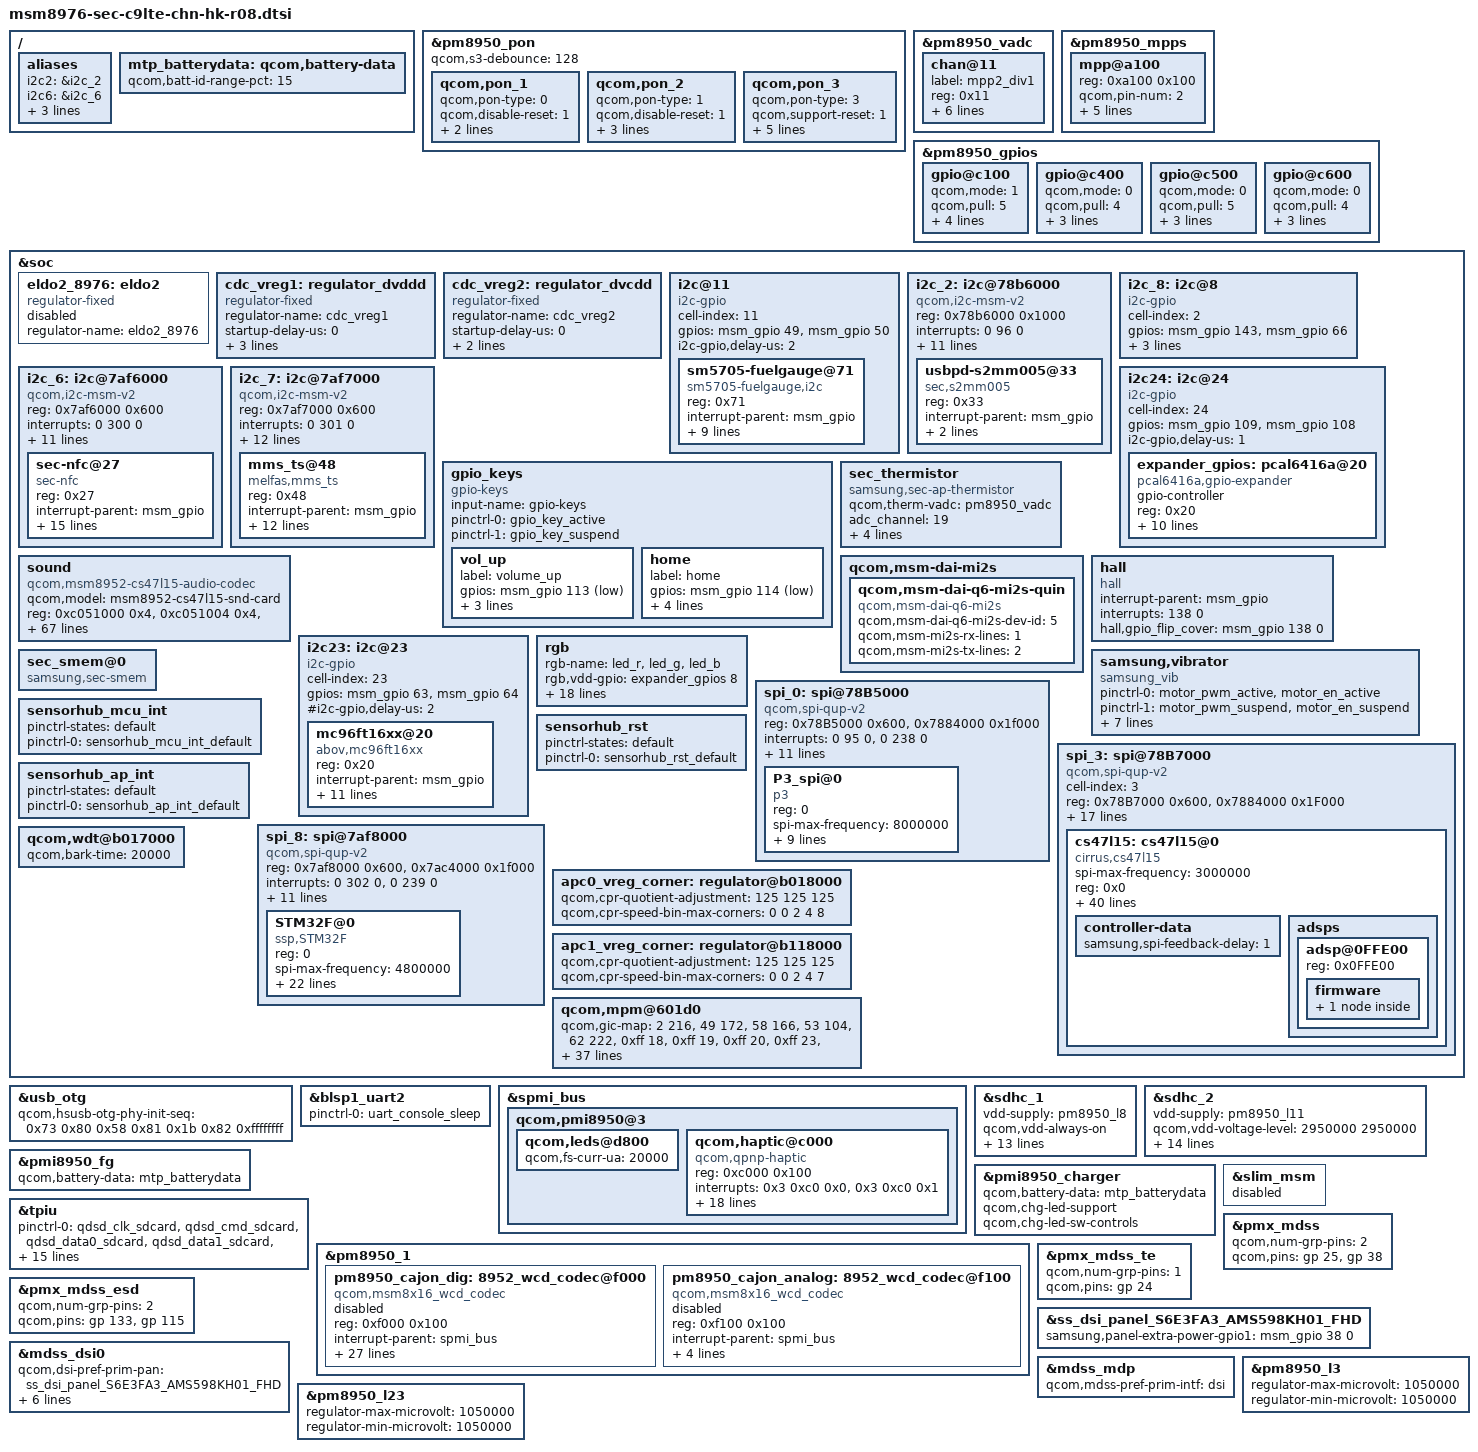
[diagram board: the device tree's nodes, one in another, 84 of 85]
/*
 * Copyright (c) 2015, The Linux Foundation. All rights reserved.
 *
 * This program is free software; you can redistribute it and/or modify
 * it under the terms of the GNU General Public License version 2 and
 * only version 2 as published by the Free Software Foundation.
 *
 * This program is distributed in the hope that it will be useful,
 * but WITHOUT ANY WARRANTY; without even the implied warranty of
 * MERCHANTABILITY or FITNESS FOR A PARTICULAR PURPOSE.  See the
 * GNU General Public License for more details.
 */

#include "../../qcom/msm8976-v1.1.dtsi"
#include "../../qcom/msm8976-pinctrl.dtsi"
#include "msm8976-sec-msm8976lte-common.dtsi"
//#include "msm8976-max77843.dtsi"
#include "msm8976-sec-pinctrl-c9lte-chn-hk-r08.dtsi"
#include "msm8976-sec-c9lte-chn-fingerprint-sensor_01.dtsi"
#include "msm8976-c9lte-sm5705-r02.dtsi"
#include "msm8976-sec-c9lte-chn-battery-r02.dtsi"
//#include "msm8976-sm5705.dtsi"
//#include "msm8976-s2mpb02.dtsi"
#include "msm8976-sec-a9xlte-chn-mst-r02.dtsi"
#include "msm8976-camera-sensor-c9lte-r01.dtsi"

/{
	aliases {
		i2c2 = &i2c_2;
		//i2c5 = &i2c_5;
		i2c6 = &i2c_6;
		i2c8 = &i2c_8;
		spi3 = &spi_3;
		spi8 = &spi_8;
	};
};

&pm8950_pon {
	qcom,s3-debounce = <128>;

	qcom,pon_1 {
		qcom,pon-type = <0>;
		qcom,disable-reset = <1>;
		qcom,pull-up = <1>;
		linux,code = <116>;
	};

	qcom,pon_2 {
		qcom,pon-type = <1>;
		qcom,disable-reset = <1>;
		qcom,support-reset = <0>;
		qcom,pull-up = <1>;
		linux,code = <114>;
	};

	qcom,pon_3 {
		qcom,pon-type = <3>;
		qcom,support-reset = <1>;
		qcom,pull-up = <1>;
		qcom,s1-timer = <6720>;
		qcom,s2-timer = <1000>;
		qcom,s2-type = <1>;
		qcom,use-bark;
	};
};

&pm8950_vadc {
	chan@11 {
		label = "mpp2_div1";
		reg = <0x11>;
		qcom,decimation = <0>;
		qcom,pre-div-channel-scaling = <0>; // 1:3scale
		qcom,calibration-type = "absolute";
		qcom,scale-function = <0>;
		qcom,hw-settle-time = <2>;
		qcom,fast-avg-setup = <0>;
	};
};

&pm8950_mpps {
	mpp@a100 {
		reg = <0xa100 0x100>;
		qcom,pin-num = <2>;
		status = "okay";
		qcom,mode = <4>; /* AIN input */
		qcom,invert = <1>; /* Enable MPP */
		qcom,ain-route = <1>; /* AMUX 6 */
		qcom,master-en = <1>;
		qcom,src-sel = <0>; /* Function constant */
	};
};

&pm8950_gpios {
	gpio@c100 {
		qcom,mode = <1>; // Digital output
		qcom,pull = <5>; // No Pull up
		qcom,vin-sel = <2>; // Vin select to 1 i.e.,  V
		qcom,src-sel = <2>; //special function 1
		qcom,master-en = <1>; //enable MPP
		qcom,out-strength = <2>; // Output strength medium
		status = "ok";
	};
	gpio@c400 {
                qcom,mode = <0>;
                qcom,pull = <4>;
                qcom,vin-sel = <2>;
                qcom,src-sel = <2>;
                qcom,master-en = <1>;
                status = "ok";
        };
	gpio@c500 {
		status = "ok";
		qcom,mode = <0>;
		qcom,pull = <5>;
		qcom,vin-sel = <3>;//VREG_L5, 1.8V
		qcom,src-sel = <0>;
		qcom,master-en = <1>;
	};
	gpio@c600 {
		status = "ok";
		qcom,mode = <0>;
		qcom,pull = <4>;
		qcom,vin-sel = <3>;//VREG_L5, 1.8V
		qcom,src-sel = <0>;
		qcom,master-en = <1>;
	};	
};

&soc {

	eldo2_8976: eldo2 {
		compatible = "regulator-fixed";
		regulator-name = "eldo2_8976";
		status = "disabled";
	};
		
	cdc_vreg1: regulator_dvddd {
        compatible = "regulator-fixed";
        regulator-name = "cdc_vreg1";
		status = "ok";
        startup-delay-us = <0>;
        enable-active-high;
        gpio = <&msm_gpio 74 0>;
		regulator-always-on;
    };

    cdc_vreg2: regulator_dvcdd {
        compatible = "regulator-fixed";
        regulator-name = "cdc_vreg2";
        startup-delay-us = <0>;
        enable-active-high;
		status = "ok";
        gpio = <&msm_gpio 75 0>;
    };

	i2c@11 {
		cell-index = <11>;
		compatible = "i2c-gpio";
		gpios = <&msm_gpio 49 0 /* sda */
			&msm_gpio 50 0	/* scl */
			>;
		i2c-gpio,delay-us = <2>;
		#address-cells = <1>;
		#size-cells = <0>;

		sm5705-fuelgauge@71{
			compatible = "sm5705-fuelgauge,i2c";
			reg = <0x71>;
			interrupt-parent = <&msm_gpio>;
			pinctrl-names = "default";
			pinctrl-0 = <&fg_i2c_active &fuel_int_active>;
			fuelgauge,irqf = "IRQF_TRIGGER_FALLING + IRQF_ONESHOT + IRQF_NO_SUSPEND";
			fuelgauge,fuel_int = <&msm_gpio 141 0x1>;
			fuelgauge,fuel_alert_soc = <1>;
			fuelgauge,capacity_max = <1000>;
			fuelgauge,capacity_max_margin = <70>;
			fuelgauge,capacity_min = <0>;
			fuelgauge,capacity_calculation_type = <0x1F>;
		};
	};


	i2c_2: i2c@78b6000 { /* BLSP1 QUP2 */
		compatible = "qcom,i2c-msm-v2";
		#address-cells = <1>;
		#size-cells = <0>;
		reg-names = "qup_phys_addr";
		reg = <0x78b6000 0x1000>;
		interrupt-names = "qup_irq";
		interrupts = <0 96 0>;
		qcom,clk-freq-out = <100000>;
		qcom,clk-freq-in  = <19200000>;
		clock-names = "iface_clk", "core_clk";
		clocks = <&clock_gcc clk_gcc_blsp1_ahb_clk>,
			<&clock_gcc clk_gcc_blsp1_qup2_i2c_apps_clk>;
		pinctrl-names = "i2c_active", "i2c_sleep";
		pinctrl-0 = <&i2c_2_active &s2mm005_irq_default>; 
		pinctrl-1 = <&i2c_2_sleep>;
		qcom,noise-rjct-scl = <0>;
		qcom,noise-rjct-sda = <0>;
		qcom,master-id = <86>;
		dmas = <&dma_blsp1 6 64 0x20000020 0x20>,
               		<&dma_blsp1 7 32 0x20000020 0x20>;
		dma-names = "tx", "rx";


		usbpd-s2mm005@33 {
			compatible = "sec,s2mm005";
			reg = <0x33>;
			interrupt-parent = <&msm_gpio>;
			interrupts = <107 0x0>;
			usbpd,usbpd_int = <&msm_gpio 107 0>;
		};
	};
	
	i2c_8:i2c@8 { /* SW I2C */
		cell-index = <2>;
		compatible = "i2c-gpio";
		gpios = <&msm_gpio 143 0 /* sda */
			&msm_gpio 66 0 /* scl */
		>;
		#i2c-gpio,delay-us = <2>;
		#address-cells = <1>;
		#size-cells = <0>;
		pinctrl-names = "default";
		pinctrl-0 = <&i2c_1_active>;
		pinctrl-1 = <&i2c_1_sleep>;
	
	};

#if 0
	i2c_5: i2c@7af5000 { /* BLSP2 QUP1 */
		compatible = "qcom,i2c-msm-v2";
		#address-cells = <1>;
		#size-cells = <0>;
		reg-names = "qup_phys_addr";
		reg = <0x7af5000 0x1000>;
		interrupt-names = "qup_irq";
		interrupts = <0 299 0>;
		qcom,clk-freq-out = <400000>;
		qcom,clk-freq-in  = <19200000>;
		clock-names = "iface_clk", "core_clk";
		clocks = <&clock_gcc clk_gcc_blsp2_ahb_clk>,
			 <&clock_gcc clk_gcc_blsp2_qup1_i2c_apps_clk>;

		pinctrl-names = "i2c_active", "i2c_sleep";
		pinctrl-0 = <&i2c_5_active>;
		pinctrl-1 = <&i2c_5_suspend>;
		qcom,noise-rjct-scl = <0>;
		qcom,noise-rjct-sda = <0>;
		qcom,master-id = <84>;
		dmas = <&dma_blsp2 4 64 0x20000020 0x20>,
			<&dma_blsp2 5 32 0x20000020 0x20>;
		dma-names = "tx", "rx";

		bhy@28 {
			compatible = "bhy";
			reg = <0x28>;
			interrupt-parent = <&msm_gpio>;
			interrupts = <142 0>;
			bhy,gpio_irq = <&msm_gpio 142 0x00>;
			bhy,ldo_enable = <&msm_gpio 69 0x01>;
			bhy,i2c-pull-up = <1>;
		};
	};
#endif
	i2c_6: i2c@7af6000 { /* BLSP2 QUP2 */
		compatible = "qcom,i2c-msm-v2";
		#address-cells = <1>;
		#size-cells = <0>;
		reg-names = "qup_phys_addr";
		reg = <0x7af6000 0x600>;
		interrupt-names = "qup_irq";
		interrupts = <0 300 0>;
		qcom,clk-freq-out = <400000>;
		qcom,clk-freq-in  = <19200000>;
		clock-names = "iface_clk", "core_clk";
		clocks = <&clock_gcc clk_gcc_blsp2_ahb_clk>,
			<&clock_gcc clk_gcc_blsp2_qup2_i2c_apps_clk>;
		pinctrl-names = "i2c_active", "i2c_sleep";
		pinctrl-0 = <&i2c_6_active>;
		pinctrl-1 = <&i2c_6_sleep>;
		qcom,noise-rjct-scl = <0>;
		qcom,noise-rjct-sda = <0>;
		qcom,master-id = <84>;
		dmas = <&dma_blsp2 6 64 0x20000020 0x20>,
			<&dma_blsp2 7 32 0x20000020 0x20>;
		dma-names = "tx", "rx";

		sec-nfc@27 {
			compatible = "sec-nfc";
			reg = <0x27>;
			interrupt-parent = <&msm_gpio>;
			interrupts = <21 0>;
			pinctrl-names = "nfc_active","nfc_suspend";
			pinctrl-0 = <&nfc_int_active &nfc_firmware_active &nfc_enable_active &nfc_pvdd_active>;
			pinctrl-1 = <&nfc_int_suspend &nfc_firmware_suspend &nfc_enable_suspend &nfc_pvdd_suspend>;
			sec-nfc,firm-gpio = <&msm_gpio 36 0x00>;
			sec-nfc,ven-gpio = <&msm_gpio 20 0x00>;
			sec-nfc,irq-gpio = <&msm_gpio 21 0x00>;
			sec-nfc,pvdd-gpio = <&msm_gpio 35 0x00>;
			qcom,clk-src = "BBCLK2";
			qcom,clk-gpio = <&pm8950_gpios 5 0x00>;
			clocks = <&clock_gcc clk_bb_clk2_pin>;
			clock-names = "rf_clk";
			sec-nfc,nfc_pm_clk;
		};
	};

	i2c_7: i2c@7af7000 { /* BLSP2 QUP3 */
		compatible = "qcom,i2c-msm-v2";
		#address-cells = <1>;
		#size-cells = <0>;
		reg-names = "qup_phys_addr";
		reg = <0x7af7000 0x600>;
		interrupt-names = "qup_irq";
		interrupts = <0 301 0>;
		qcom,master-id = <84>;
		qcom,clk-freq-out = <400000>;
		qcom,clk-freq-in  = <19200000>;
		clock-names = "iface_clk", "core_clk";
		clocks = <&clock_gcc clk_gcc_blsp2_ahb_clk>,
			<&clock_gcc clk_gcc_blsp2_qup3_i2c_apps_clk>;
		pinctrl-names = "i2c_active", "i2c_sleep";
		pinctrl-0 = <&i2c_7_active>;
		pinctrl-1 = <&i2c_7_suspend>;
		qcom,noise-rjct-scl = <0>;
		qcom,noise-rjct-sda = <0>;
		qcom,disable-dma;
		dmas = <&dma_blsp2 8 64 0x20000020 0x20>,
			<&dma_blsp2 9 32 0x20000020 0x20>;
		dma-names = "tx", "rx";
	};

	i2c24: i2c@24 { /* SW I2C */
		cell-index = <24>;
		compatible = "i2c-gpio";
		gpios = <&msm_gpio 109 0 /* sda */
			&msm_gpio 108 0 /* scl */
		>;
		i2c-gpio,delay-us = <1>;
		#address-cells = <1>;
		#size-cells = <0>;

		expander_gpios: pcal6416a@20 {
			compatible = "pcal6416a,gpio-expander";
			gpio-controller;
			#gpio-cells = <2>;
			reg = <0x20>;
			pinctrl-names = "expander_reset_setting";
			pinctrl-0 = <&expander_reset_active &expander_i2c_active>;
			pcal6416a,gpio_start = <300>;
			pcal6416a,ngpio = <16>;
			pcal6416a,reset-gpio = <&msm_gpio 51 0x00>;
			pcal6416a,vdd-supply = <&pm8950_l5>;
			pcal6416a,support_initialize = <1>;
			/* config, 15 ~ 0, 1bit configure[1:input, 0:output]*/
			pcal6416a,config = <0x5EE0>;    /* 0101 1110 1110 0000 */
			/* data_out, 15 ~ 0, 1bit configure[1:high, 0:low]*/
			pcal6416a,data_out = <0x0000>;  /* 0000 0000 0000 0000  */
			/* pull_reg, 31 ~ 0, 2bit configure[00:no_pull, 01:pull_down, 10:pull_up, 11:not used]*/
			pcal6416a,pull_reg = <0x04000145>; /* 00 00 01 00 / 00 00 00 00 /  00 00 00 01 / 01 00 01 01 */
		};
	};

	gpio_keys {
		compatible = "gpio-keys";
		input-name = "gpio-keys";
		pinctrl-names = "tlmm_gpio_key_active","tlmm_gpio_key_suspend";
		pinctrl-0 = <&gpio_key_active>;
		pinctrl-1 = <&gpio_key_suspend>;

		vol_up {
			label = "volume_up";
			gpios = <&msm_gpio 113 0x1>;
			linux,input-type = <1>;
			linux,code = <115>;
			debounce-interval = <15>;
		};

		home {
			label = "home";
			gpios = <&msm_gpio 114 0x1>;
			linux,input-type = <1>;
			linux,code = <172>;
			gpio-key,wakeup;
			debounce-interval = <15>;
		};
	};

	sec_thermistor {
		compatible = "samsung,sec-ap-thermistor";
		qcom,therm-vadc = <&pm8950_vadc>;
		status = "okay";
		adc_channel = <19>;
		adc_array = <25724 26467 26647 27010 27342 27620 27790 27976 28195 28425 28679 28962 29162 29405 29799 30559 31394 32464 33361 34338 35634 36245 37056 37585 37919 38083 38861 39764 40457 41041 41518>;

		temp_array = <900 800 750 700 650 620 600 580 570 550 530 510 490 470 450 400 350 300 250 200 150 100 80 50 30 10 0 (-50) (-100) (-150) (-200)>;
	};

	/delete-node/ wcd_gpio_ctrl;
	/delete-node/ sound-9335;

	sound {
		compatible = "qcom,msm8952-cs47l15-audio-codec";
		qcom,model = "msm8952-cs47l15-snd-card";
		reg = <0xc051000 0x4>,
		      <0xc051004 0x4>,
		      <0xc055000 0x4>,
		      <0xc052000 0x4>;
		reg-names = "csr_gp_io_mux_mic_ctl",
			    "csr_gp_io_mux_spkr_ctl",
			    "csr_gp_io_lpaif_pri_pcm_pri_mode_muxsel",
			    "csr_gp_io_mux_quin_ctl";

		qcom,mpp-channel-scaling = <2 1 1>;
		qcom,earjack-read-vadc = <&pm8950_vadc>;
		qcom,msm-ext-pa = "quaternary";
		qcom,msm-mclk-freq = <9600000>;
		qcom,msm-mbhc-hphl-swh = <0>;
		qcom,msm-mbhc-gnd-swh = <0>;
		qcom,msm-hs-micbias-type = "internal";
		qcom,audio-routing =
			"RX_BIAS", "MCLK",
			"SPK_RX_BIAS", "MCLK",
			"INT_LDO_H", "MCLK",
			"MainMic","MICBIAS1B",
			"IN1AL","MainMic",
			"SubMic","MICBIAS1C",
			"IN1AR","SubMic",
			"HeadsetMic","MICBIAS1A",
			"IN1BL","HeadsetMic";
		qcom,msm-gpios =
			"quat_i2s",
			"quin_i2s";
		qcom,pinctrl-names =
			"all_off",
			"quat_i2s_act",
			"quin_i2s_act",
			"quin_quat_i2s_act";
		pinctrl-names =
			"all_off",
			"quat_i2s_act",
			"quin_i2s_act",
			"quin_quat_i2s_act";
		pinctrl-0 = <&quat_tlmm_lines_sus &quat_tlmm_lines2_sus &quin_tlmm_lines_sus &gp_clk1_suspend>;
		pinctrl-1 = <&quat_tlmm_lines_act &quat_tlmm_lines2_act &quin_tlmm_lines_sus &gp_clk1_suspend>;
		pinctrl-2 = <&quat_tlmm_lines_sus &quat_tlmm_lines2_sus &quin_tlmm_lines_act &gp_clk1_active>;
		pinctrl-3 = <&quat_tlmm_lines_act &quat_tlmm_lines2_act &quin_tlmm_lines_act &gp_clk1_active>;
		asoc-platform = <&pcm0>, <&pcm1>, <&pcm2>, <&voip>, <&voice>,
				<&loopback>, <&compress>, <&hostless>,
				<&afe>, <&lsm>, <&routing>, <&lpa>,
				<&voice_svc>;
		asoc-platform-names = "msm-pcm-dsp.0", "msm-pcm-dsp.1", "msm-pcm-dsp.2",
				"msm-voip-dsp", "msm-pcm-voice", "msm-pcm-loopback",
				"msm-compress-dsp", "msm-pcm-hostless", "msm-pcm-afe",
				"msm-lsm-client", "msm-pcm-routing", "msm-pcm-lpa",
				"msm-voice-svc";
		asoc-cpu = <&dai_pri_auxpcm>, <&dai_hdmi>,
				<&dai_mi2s0>, <&dai_mi2s1>, <&dai_mi2s2>, <&dai_mi2s3>,
				<&dai_mi2s5>, <&dai_mi2s6>,
				<&sb_0_rx>, <&sb_0_tx>, <&sb_1_rx>, <&sb_1_tx>,
				<&sb_3_rx>, <&sb_3_tx>, <&sb_4_rx>, <&sb_4_tx>,
				<&bt_sco_rx>, <&bt_sco_tx>, <&int_fm_rx>, <&int_fm_tx>,
				<&afe_pcm_rx>, <&afe_pcm_tx>, <&afe_proxy_rx>, <&afe_proxy_tx>,
				<&incall_record_rx>, <&incall_record_tx>, <&incall_music_rx>,
				<&incall_music_2_rx>;
		asoc-cpu-names = "msm-dai-q6-auxpcm.1", "msm-dai-q6-hdmi.8",
				"msm-dai-q6-mi2s.0", "msm-dai-q6-mi2s.1",
				"msm-dai-q6-mi2s.2", "msm-dai-q6-mi2s.3",
				"msm-dai-q6-mi2s.5", "msm-dai-q6-mi2s.6",
				"msm-dai-q6-dev.16384", "msm-dai-q6-dev.16385",
				"msm-dai-q6-dev.16386", "msm-dai-q6-dev.16387",
				"msm-dai-q6-dev.16390", "msm-dai-q6-dev.16391",
				"msm-dai-q6-dev.16392", "msm-dai-q6-dev.16393",
				"msm-dai-q6-dev.12288", "msm-dai-q6-dev.12289",
				"msm-dai-q6-dev.12292", "msm-dai-q6-dev.12293",
				"msm-dai-q6-dev.224", "msm-dai-q6-dev.225",
				"msm-dai-q6-dev.241", "msm-dai-q6-dev.240",
				"msm-dai-q6-dev.32771", "msm-dai-q6-dev.32772",
				"msm-dai-q6-dev.32773", "msm-dai-q6-dev.32770";
		asoc-codec = <&stub_codec>, <&pm8950_cajon_dig>;
		asoc-codec-names = "msm-stub-codec.1", "cajon_codec";
		
		clock-names = "ext-mclk";
		clocks = <&clock_gcc clk_gcc_camss_gp1_clk>;
		
		imp_table = <
			0 13 8
			14 26 8
			27 42 8
			43 100 19
			101 200 19
			201 450 19
			451 1000 19
			1001 9999 19
		>;
	};

	qcom,msm-dai-mi2s {
		qcom,msm-dai-q6-mi2s-quin {
			compatible = "qcom,msm-dai-q6-mi2s";
			qcom,msm-dai-q6-mi2s-dev-id = <5>;
			qcom,msm-mi2s-rx-lines = <1>;
			qcom,msm-mi2s-tx-lines = <2>;
		};
	};

	hall {
		status = "okay";
		compatible = "hall";
		interrupt-parent = <&msm_gpio>;
		interrupts = <138 0>;
		hall,gpio_flip_cover = <&msm_gpio 138 0>;
	};
#if 0
	certify_hall {
                status = "okay";
                compatible = "certify_hall";
                interrupt-parent = <&msm_gpio>;
                interrupts = <144 0>;
                certify_hall,gpio_certify_cover = <&msm_gpio 144 0>;
        };
#endif
	i2c23: i2c@23 { /* SW I2C */
		cell-index = <23>;
		compatible = "i2c-gpio";
		gpios = <&msm_gpio 63 0 /* sda */
			&msm_gpio 64 0 /* scl */
		>;
		#i2c-gpio,delay-us = <2>;
		#address-cells = <1>;
		#size-cells = <0>;

		mc96ft16xx@20{
			compatible = "abov,mc96ft16xx";
			reg = <0x20>;
			interrupt-parent = <&msm_gpio>;
			interrupts = <62 0>;
			pinctrl-names = "touchkey_active", "touchkey_suspend";
			pinctrl-0 = <&touchkey_i2c_active &touchkey_int_active>;
			pinctrl-1 = <&touchkey_i2c_suspend &touchkey_int_suspend>;
			abov,sda-gpio = <&msm_gpio 63 0>;
			abov,scl-gpio = <&msm_gpio 64 0>;
			abov,irq-gpio = <&msm_gpio 62 0>;
			abov,tkey_en-gpio = <&pm8950_gpios 7 0x00>;
			abov,firmware_name = "abov/abov_ft1604_c9.fw";
			vdd_led-supply = <&pm8950_l10>;
			//abov,tkey_led_en-gpio = <&msm_gpio 91 0>;
			//vddo-supply = <&pm8950_l6>;
		};
	};

	samsung,vibrator {
               compatible = "samsung_vib";
               pinctrl-names = "tlmm_motor_active","tlmm_motor_suspend";
               pinctrl-0 = <&motor_pwm_active &motor_en_active>;
               pinctrl-1 = <&motor_pwm_suspend &motor_en_suspend>;
	       samsung,vib_en = <&msm_gpio 118 1>;
               samsung,vib_pwm = <&msm_gpio 31 0x1>;
               samsung,gp_clk = <0x01854000>;   // Address of GP1 clock
               samsung,chip_model = <2>;         // using ISA driver
	       samsung,m_default = <3>;
	       samsung,n_default = <138>;
	       samsung,motor_strength = <98>;
               status = "ok";
       };

	rgb {
		device_type = <0>;
		rgb-name = "led_r", "led_g", "led_b";
		rgb,vdd-gpio = <&expander_gpios 8 0x0>;

		normal_powermode_current = <255>;
		low_powermode_current = <51>;
		br_ratio_r = <27>;
		br_ratio_g = <9>;
		br_ratio_b = <80>;
		br_ratio_b_low = <32>;

		normal_powermode_current_bk = <255>;
		low_powermode_current_bk = <51>;
		br_ratio_r_bk = <25>;
		br_ratio_g_bk = <9>;
		br_ratio_b_bk = <80>;
		br_ratio_b_low_bk = <32>;

		normal_powermode_current_wt = <255>;
		low_powermode_current_wt = <51>;
		br_ratio_r_wt = <27>;
		br_ratio_g_wt = <9>;
		br_ratio_b_wt = <80>;
		br_ratio_b_low_wt = <32>;
	};
	/delete-node/ spi@0x78B5000;

	spi_0: spi@78B5000 { /* BLSP1 QUP0 */
		status = "ok";
		compatible = "qcom,spi-qup-v2";
                #address-cells = <1>;
                #size-cells = <0>;
		reg-names = "spi_physical", "spi_bam_physical";
                reg = <0x78B5000 0x600>, <0x7884000 0x1f000>;
		interrupt-names = "spi_irq", "spi_bam_irq";
		interrupts = <0 95 0>, <0 238 0>;
		spi-max-frequency = <19200000>;
                qcom,master-id = <86>;

                qcom,use-bam;
                qcom,use-pinctrl;
                qcom,ver-reg-exists;
                qcom,bam-consumer-pipe-index = <4>;
                qcom,bam-producer-pipe-index = <5>;
		pinctrl-names = "spi_default", "spi_sleep";
		pinctrl-0 = <&spi0_default &spi0_cs0_active>;
		pinctrl-1 = <&spi0_sleep &spi0_cs0_sleep>;

                clock-names = "iface_clk", "core_clk";
		clocks = <&clock_gcc clk_gcc_blsp1_ahb_clk>,
			 <&clock_gcc clk_gcc_blsp1_qup1_spi_apps_clk>;

		P3_spi@0 {
			compatible = "p3";
			reg = <0>;
			spi-max-frequency = <8000000>;
			p3-mosipin = <&msm_gpio 0 0x0>;
			p3-misopin = <&msm_gpio 1 0x0>;
			p3-cspin = <&msm_gpio 2 0x0>;
			p3-clkpin = <&msm_gpio 3 0x0>;
			p3-ese_pwr_req = <&msm_gpio 100 0x0>;
			p3-test = <0xBB>;
			p3-ap_vendor = "qualcomm";
			clock-names = "pclk", "sclk";
			clocks = <&clock_gcc clk_gcc_blsp1_ahb_clk>,
			       <&clock_gcc clk_gcc_blsp1_qup1_spi_apps_clk>;
		};
	};
		
	spi_3: spi@78B7000 {
		status = "ok";
		compatible = "qcom,spi-qup-v2";
		cell-index = <3>;
		reg-names = "spi_physical", "spi_bam_physical";
		reg = <0x78B7000 0x600>,
			<0x7884000 0x1F000>;
		interrupt-names = "spi_irq", "spi_bam_irq";
		interrupts = <0 97 0>, <0 238 0>;
		spi-max-frequency = <19200000>;
		#address-cells = <1>;
		#size-cells = <0>;

		qcom,gpio-mosi = <&msm_gpio 8 0>;
		qcom,gpio-miso = <&msm_gpio 9 0>;
		qcom,gpio-cs0  = <&msm_gpio 10 0>;
		qcom,gpio-clk  = <&msm_gpio 11 0>;

		qcom,infinite-mode = <0>;
		qcom,use-bam;
		qcom,use-pinctrl;
		qcom,bam-consumer-pipe-index = <8>;
		qcom,bam-producer-pipe-index = <9>;
		qcom,ver-reg-exists;
		qcom,master-id = <86>;

		pinctrl-names = "spi_default", "spi_sleep";
		pinctrl-0 = <&spi_3_active &spi_3_clk_active>;
		pinctrl-1 = <&spi_3_sleep &spi_3_clk_sleep>;

		clock-names = "iface_clk", "core_clk";
		clocks = <&clock_gcc clk_gcc_blsp1_ahb_clk>,
		<&clock_gcc clk_gcc_blsp1_qup3_spi_apps_clk>;
		
		cs47l15: cs47l15@0 {
			spi-max-frequency = <3000000>;

			compatible = "cirrus,cs47l15";
			reg = <0x0>;
			interrupt-parent = <&msm_gpio>;
            interrupts = <121 0>;
			interrupt-controller;
			#interrupt-cells = <2>;
			//interrupt-parent = <&gpx0>;
			gpio-controller;
			#gpio-cells = <2>;
			
			
			AVDD-supply = <&cdc_vreg1>;
            DCVDD-supply = <&cdc_vreg2>;
            DBVDD1-supply = <&cdc_vreg1>;
            CPVDD-supply = <&cdc_vreg1>;
            MICVDD-supply = <&cdc_vreg1>;
			SPKVDD-supply = <&pm8950_l5>;

			wlf,reset = <&msm_gpio 116 0>;
			//wlf,ldoena = <&expander_gpios 12 1>;//<&msm_gpio 75 0>;
			wlf,micd-bias-start-time = <1>;
			wlf,gpsw = <3>;
			wlf,micd-rate = <7>;
			wlf,micd-dbtime = <0x1>;
			wlf,micd-timeout = <1000>;
			wlf,micd-force-micbias;
			wlf,hpdet-short-circuit-imp = <3>;
			wlf,jd-wake-time = <5000>;
			wlf,micd-open-circuit-declare = <1>;
			
			// Moisture Detection
			wlf,hpdet-moisture-imp = <2000>;
			wlf,hpdet-moisture-debounce = <40>;
			
			wlf,micd-detect-debounce = <300>;
			wlf,micbias1 = <2800 0 1 1 1 1 0>;
			wlf,dmic-ref = <0 0 0>;
			wlf,inmode = <0 0 0>;
			wlf,hs-mic = <1>;
			wlf,hpdet-ext-res = <8>;
			wlf,micd-configs = <1 0 0 0>;
			wlf,micd-ranges = <
			 116 226
			 173 582
			 321 115
			 752 114
			 1257 217
			>;
			wlf,micd-clamp-mode = <0x8>;
			wlf,use-jd-gpio;
			wlf,micd-software-compare;
			wlf,init-mic-delay = <30>;
			
			wlf,dvbdd_ena = <&expander_gpios 10 1>;
			wlf,dcvdd_ena = <&expander_gpios 12 1>;//<&msm_gpio 75 0>;
			wlf,ear_switch_ena = <&expander_gpios 9 1>;

			wlf,gpio-defaults = <
				0x00002000 0x00006000 /* AIF1TXDAT (GPIO1) */
				0x00002000 0x00006000 /* AIF1RXDAT (GPIO2) */
				0x00002000 0x00006000 /* AIF1BCLK (GPIO3) */
				0x00002000 0x00006000 /* AIF1LRCLK (GPIO4) */
				0x00002000 0x00006000 /* AIF2TXDAT (GPIO5) */
				0x00002000 0x00006000 /* AIF2RXDAT (GPIO6) */
				0x00002000 0x00006000 /* AIF2BCLK (GPIO7) */
				0x00002000 0x00006000 /* AIF2LRCLK (GPIO8) */
				0x00002000 0x00006000 /* AIF3TXDAT (GPIO9) */
				0x00002000 0x00006000 /* AIF3RXDAT (GPIO10) */
				0x00002000 0x00006000 /* AIF3BCLK (GPIO11) */
				0x00002000 0x00006000 /* AIF3LRCLK (GPIO12) */
				0x00002000 0x00006000 /* SPKTXDAT (GPIO13) */
				0x00002000 0x00006000 /* SPKCLK (GPIO14) */
				0x00002000 0x00006000 /* SPKRXDAT (GPIO15) */
			>;

			controller-data {
				//cs-gpio = <&gpf1 1 1>;
				samsung,spi-feedback-delay = <1>;
			};
			
			adsps {
				#address-cells = <1>;
				#size-cells = <0>;
				adsp@0FFE00 {
					reg = <0x0FFE00>;
					firmware {
						KARAOKE {
							wlf,wmfw-file = "karaoke-vocals";
							wlf,bin-file = "karaoke-vocals";
						};
					};
				};
			};
      	
		};
		
	};
	sec_smem@0 {
		compatible = "samsung,sec-smem";
		status = "okay";
	};

	sensorhub_mcu_int {
		pinctrl-states = "default";
		pinctrl-0 = <&sensorhub_mcu_int_default>;
		status = "ok";
				};

	sensorhub_ap_int {
		pinctrl-states = "default";
		pinctrl-0 = <&sensorhub_ap_int_default>;
		status = "ok";
				};

	sensorhub_rst {
		pinctrl-states = "default";
		pinctrl-0 = <&sensorhub_rst_default>;
		status = "ok";
				};

	spi_8: spi@7af8000 { /*BLSP2 QUP4  */
		status = "ok";
		compatible = "qcom,spi-qup-v2";
		//cell-index = <8>;
		#address-cells = <1>;
		#size-cells = <0>;
		reg-names = "spi_physical", "spi_bam_physical";
		reg = <0x7af8000 0x600>, <0x7ac4000 0x1f000>;
		interrupt-names = "spi_irq", "spi_bam_irq";
		interrupts = <0 302 0>, <0 239 0>;
		spi-max-frequency = <19200000>;

		qcom,master-id = <84>;

		qcom,ver-reg-exists;
		qcom,use-pinctrl;
		qcom,use-bam;
		qcom,bam-consumer-pipe-index = <10>;
		qcom,bam-producer-pipe-index = <11>;
		pinctrl-names = "spi_default", "spi_sleep";
		pinctrl-0 = <&spi_8_active>;
		pinctrl-1 = <&spi_8_sleep>;

		clock-names = "iface_clk", "core_clk";
		clocks = <&clock_gcc clk_gcc_blsp2_ahb_clk>,
			 <&clock_gcc clk_gcc_blsp2_qup4_spi_apps_clk>;

		STM32F@0 {
			status = "ok";
			compatible = "ssp,STM32F";
			reg = <0>;
			spi-max-frequency = <4800000>;
			interrupt-parent = <&msm_gpio>;
			interrupts = <142 0>;
			hub_vreg-supply = <&pm8950_l5>;//hub power 
			ssp,mcu_int1-gpio = <&msm_gpio 142 0x00>;
			ssp,mcu_int2-gpio = <&msm_gpio 34 0x00>;
			ssp,ap_int-gpio = <&msm_gpio 139 0x00>;
			ssp,rst-gpio = <&msm_gpio 117 0x00>;
			ssp,boot0-gpio = <&msm_gpio 126 0x00>;
			ssp,acc-position = <0>;
			ssp,mag-position = <2>;
			ssp,prox-hi_thresh = <100>;
			ssp,prox-low_thresh = <70>;
			ssp-mag-array = /bits/ 8 <89 81 54 111 17 187 255 139 216
						  54 186 235 1 179 255 179 0 17
						  133 93 192 250 166 33 8 5 210>;
			ssp-mag-type = <1>;
			ssp-acc-type = <1>;
			ssp,ap-rev=<5>;

			pinctrl-names = "default", "sleep";
			pinctrl-0 = <&sensorhub_mcu_int_default &sensorhub_ap_int_default &sensorhub_rst_default>;
			pinctrl-1 = <&sensorhub_mcu_int_sleep &sensorhub_ap_int_sleep &sensorhub_rst_sleep>;
		};
	};

	/* APC0 / APC 1 / GFX CPR nodes */
	apc0_vreg_corner: regulator@b018000 {

		/delete-property/ qcom,cpr-fuse-version-map;
		/delete-property/ qcom,cpr-scaled-init-voltage-as-ceiling;
		qcom,cpr-quotient-adjustment =
				<125 125 125>; /* All modes + 50mV */
		qcom,cpr-speed-bin-max-corners =
				<0 0 2 4 8>;
	};

	apc1_vreg_corner: regulator@b118000 {

		/delete-property/ qcom,cpr-fuse-version-map;
	/delete-property/ qcom,cpr-scaled-init-voltage-as-ceiling;
		qcom,cpr-quotient-adjustment =
				<125 125 125>; /* All modes + 50mV */
		qcom,cpr-speed-bin-max-corners =
				<0 0 2 4 7>;
	};

	qcom,wdt@b017000 {
                qcom,bark-time = <20000>; /*Increasing Bark time 11sec-->20sec*/
        };

	qcom,mpm@601d0 {
		qcom,gic-map = <2 216>, /* tsens_upper_lower_int */
			<49 172>, /* usb1_hs_async_wakeup_irq */
			<58 166>, /* usb_hs_irq */
			<53 104>, /* mdss_irq */
			<62 222>, /* ee0_krait_hlos_spmi_periph_irq */
			<0xff 18>,  /* APC_qgicQTmrSecPhysIrptReq */
			<0xff 19>,  /* APC_qgicQTmrNonSecPhysIrptReq */
			<0xff 20>,  /* qgicQTmrVirtIrptReq */
			<0xff 23>,  /* APC0_qgicPerfMonIrptReq */
			<0xff 35>,  /* WDT_barkInt */
			<0xff 39>,  /* arch_mem_timer */
			<0xff 40>,  /* qtmr_phy_irq[0] */
			<0xff 47>,  /* rbif_irq[0] */
			<0xff 51>,  /* rbif_Irq[3] */
			<0xff 54>,  /* nERRORIRQ */
			<0xff 56>,  /* q6_wdog_expired_irq */
			<0xff 57>,  /* mss_to_apps_irq(0) */
			<0xff 58>,  /* mss_to_apps_irq(1) */
			<0xff 59>,  /* mss_to_apps_irq(2) */
			<0xff 60>,  /* mss_to_apps_irq(3) */
			<0xff 61>,  /* mss_a2_bam_irq */
			<0xff 65>,  /* o_gc_sys_irq[0] */
			<0xff 73>,  /* smmu_intr_bus[1] */
			<0xff 74>,  /* smmu_bus_intr[2] */
			<0xff 75>,  /* smmu_bus_intr[3] */
			<0xff 76>,  /* venus_irq */
			<0xff 78>,  /* smmu_bus_intr[5] */
			<0xff 79>,  /* smmu_bus_intr[6] */
			<0xff 85>,  /* smmu_bus_intr[31] */
			<0xff 86>,  /* smmu_bus_intr[32] */
			<0xff 90>,  /* smmu_bus_intr[33] */
			<0xff 92>,  /* smmu_bus_intr[34] */
			<0xff 93>,  /* smmu_bus_intr[35] */
			<0xff 97>,  /* smmu_bus_intr[10] */
			<0xff 102>, /* smmu_bus_intr[14] */
			<0xff 108>, /* smmu_bus_intr[36] */
			<0xff 109>, /* smmu_bus_intr[37] */
			<0xff 112>, /* smmu_bus_intr[38] */
			<0xff 114>, /* qdsd_intr_out */
			<0xff 126>, /* app_cxt_irpt_10 */
			<0xff 128>, /* blsp1_peripheral_irq[3] */
			<0xff 129>, /* blsp1_peripheral_irq[4] */
			<0xff 130>, /* qup_irq */
			<0xff 131>, /* qup_irq */
			<0xff 133>, /* app_cxt_irpt_11 */
			<0xff 134>, /* app_cxt_irpt_12 */
			<0xff 137>, /* smmu_intr_bus[44] */
			<0xff 138>, /* smmu_intr_bus[45] */
			<0xff 140>, /* uart_dm_intr */
			<0xff 141>, /* app_cxt_irpt_17 */
			<0xff 142>, /* smmu_bus_intr[47] */
			<0xff 143>, /* smmu_bus_intr[48] */
			<0xff 144>, /* smmu_bus_intr[49] */
			<0xff 145>, /* smmu_bus_intr[50] */
			<0xff 146>, /* smmu_bus_intr[51] */
			<0xff 147>, /* smmu_bus_intr[52] */
			<0xff 148>, /* smmu_bus_intr[53] */
			<0xff 149>, /* smmu_bus_intr[54] */
			<0xff 150>, /* smmu_bus_intr[55] */
			<0xff 151>, /* smmu_bus_intr[56] */
			<0xff 152>, /* smmu_bus_intr[57] */
			<0xff 153>, /* smmu_bus_intr[58] */
			<0xff 155>, /* sdc1_irq(0) */
			<0xff 157>, /* sdc2_irq(0) */
			<0xff 167>, /* usb1_hs_bam_irq */
			<0xff 170>, /* sdc1_pwr_cmd_irq */
			<0xff 173>, /* o_wcss_apss_smd_hi */
			<0xff 174>, /* o_wcss_apss_smd_med */
			<0xff 175>, /* o_wcss_apss_smd_low */
			<0xff 176>, /* o_wcss_apss_smsm_irq */
			<0xff 177>, /* o_wcss_apss_wlan_data_xfer_done */
			<0xff 178>, /* o_wcss_apss_wlan_rx_data_avail */
			<0xff 179>, /* o_wcss_apss_asic_intr */
			<0xff 181>, /* o_wcss_apss_wdog_bite_and_reset_rdy */
			<0xff 188>, /* lpass_irq_out_apcs(0) */
			<0xff 189>, /* lpass_irq_out_apcs(1) */
			<0xff 190>, /* lpass_irq_out_apcs(2) */
			<0xff 191>, /* lpass_irq_out_apcs(3) */
			<0xff 192>, /* lpass_irq_out_apcs(4) */
			<0xff 193>, /* lpass_irq_out_apcs(5) */
			<0xff 194>, /* lpass_irq_out_apcs(6) */
			<0xff 195>, /* lpass_irq_out_apcs(7) */
			<0xff 196>, /* lpass_irq_out_apcs(8) */
			<0xff 197>, /* lpass_irq_out_apcs(9) */
			<0xff 198>, /* coresight-tmc-etr interrupt */
			<0xff 200>, /* rpm_ipc(4) */
			<0xff 201>, /* rpm_ipc(5) */
			<0xff 202>, /* rpm_ipc(6) */
			<0xff 203>, /* rpm_ipc(7) */
			<0xff 204>, /* rpm_ipc(24) */
			<0xff 205>, /* rpm_ipc(25) */
			<0xff 206>, /* rpm_ipc(26) */
			<0xff 207>, /* rpm_ipc(27) */
			<0xff 212>, /* lpass_slimbus_bam_ee1_irq */
			<0xff 215>, /* o_bimc_intr[0] */
			<0xff 224>, /* spdm_realtime_irq[1] */
			<0xff 239>, /* crypto_bam_irq[1]*/
			<0xff 240>, /* summary_irq_kpss */
			<0xff 253>, /* sdc2_pwr_cmd_irq */
			<0xff 260>, /* ipa_irq[0] */
			<0xff 262>, /* ipa_bam_irq[0] */
			<0xff 269>, /* rpm_wdog_expired_irq */
			<0xff 270>, /* blsp1_bam_irq[0] */
			<0xff 272>, /* smmu_intr_bus[17] */
			<0xff 273>, /* smmu_bus_intr[18] */
			<0xff 274>, /* smmu_bus_intr[19] */
			<0xff 275>, /* rpm_ipc(30) */
			<0xff 276>, /* rpm_ipc(31) */
			<0xff 277>, /* smmu_intr_bus[20] */
			<0xff 280>, /* mobicore */
			<0xff 286>, /* app_cxt_irpt_0 */
			<0xff 287>, /* app_cxt_irpt_1 */
			<0xff 296>, /* lmh_interrupt */
			<0xff 305>, /* nEXTERRIRQ_C0 */
			<0xff 306>, /* nEXTERRIRQ_C1 */
			<0xff 307>, /* nINTERRIRQ_C0 */
			<0xff 308>, /* nINTERRIRQ_C1 */
			<0xff 321>, /* q6ss_irq_out(4) */
			<0xff 322>, /* q6ss_irq_out(5) */
			<0xff 323>, /* q6ss_irq_out(6) */
			<0xff 325>, /* q6ss_wdog_exp_irq */
			<0xff 271>, /* gic sps */
			<0xff 280>, /* gic mobicore */
			<0xff 333>, /* gic i2c-msm-v2-irq */
			<0xff 334>; /* gic 7af8000.spi */

		qcom,gpio-map = <3  100>,
			<4  1>,
			<5  5>,
			<6  9>,
			<8  106>,
			<9  119>,
			<10  133>,
			<11  135>,
			<12  12>,
			<13  13>,
			<14  138>,
			<15  139>,
			<16  140>,
			<17  21>,
			<18  52>,
			<19  25>,
			<20  141>,
			<21  142>,
			<22  28>,
			<23  144>,
			<24  17>,
			<25  33>,
			<26  56>,
			<27  60>,
			<28  38>,
			<29  107>,
			<30  109>,
			<31  45>,
			<32  67>,
			<33  112>,
			<34  113>,
			<35  114>,
			<36  115>,
			<37  68>,
			<38  118>,
			<39  120>,
			<40  121>,
			<41  102>,
			<50  105>,
			<51  130>,
			<52  65>,
			<53  131>,
			<54  39>,
			<55  41>,
			<56  35>,
			<0xff  62>;
	};

};

&usb_otg {
		qcom,hsusb-otg-phy-init-seq =
			<0x73 0x80 0x58 0x81 0x1b 0x82 0xffffffff>;
};

&blsp1_uart2 {
	status = "ok";
	pinctrl-names = "default";
	pinctrl-0 = <&uart_console_sleep>;
};


&spmi_bus {
	qcom,pmi8950@3 {
		qcom,leds@d800 {
			qcom,fs-curr-ua = <20000>;
		};

		qcom,haptic@c000 {
			compatible = "qcom,qpnp-haptic";
			reg = <0xc000 0x100>;
			interrupts = <0x3 0xc0 0x0>,
				<0x3 0xc0 0x1>;
			interrupt-names = "sc-irq", "play-irq";
			qcom,play-mode = "direct";
			qcom,wave-play-rate-us = <5263>;
			qcom,actuator-type = "lra";
			qcom,wave-shape = "square";
			qcom,vmax-mv = <2000>;
			qcom,ilim-ma = <800>;
			qcom,sc-deb-cycles = <8>;
			qcom,int-pwm-freq-khz = <505>;
			qcom,en-brake;
			qcom,brake-pattern = [03 03 00 00];
			qcom,use-play-irq;
			qcom,use-sc-irq;
			qcom,wave-samples = [3e 3e 3e 3e 3e 3e 3e 3e];
			qcom,wave-rep-cnt = <1>;
			qcom,wave-samp-rep-cnt = <1>;
			qcom,lra-auto-res-mode="qwd";
			qcom,lra-high-z="opt1";
			qcom,lra-res-cal-period = <0>;
		};
	};
};

&sdhc_1 {
	vdd-supply = <&pm8950_l8>;
	qcom,vdd-always-on;
	qcom,vdd-lpm-sup;
	qcom,vdd-voltage-level = <2900000 2900000>;
	qcom,vdd-current-level = <200 570000>;

	vdd-io-supply = <&pm8950_l5>;
	qcom,vdd-io-always-on;
	qcom,vdd-io-lpm-sup;
	qcom,vdd-io-voltage-level = <1800000 1800000>;
	qcom,vdd-io-current-level = <200 325000>;

	pinctrl-names = "active", "sleep";
	pinctrl-0 = <&sdc1_clk_on &sdc1_cmd_on &sdc1_data_on &sdc1_rclk_on>;
	pinctrl-1 = <&sdc1_clk_off &sdc1_cmd_off &sdc1_data_off &sdc1_rclk_off>;

	qcom,nonremovable;

	status = "ok";
};

&sdhc_2 {
	vdd-supply = <&pm8950_l11>;
	qcom,vdd-voltage-level = <2950000 2950000>;
	qcom,vdd-current-level = <15000 800000>;

	vdd-io-supply = <&pm8950_l12>;
	qcom,vdd-io-voltage-level = <1800000 2950000>;
	qcom,vdd-io-current-level = <200 22000>;

	pinctrl-names = "active", "sleep";
	pinctrl-0 = <&sdc2_clk_on &sdc2_cmd_on &sdc2_data_on &sdc2_cd_on>;
	pinctrl-1 = <&sdc2_clk_off &sdc2_cmd_off &sdc2_data_off &sdc2_cd_off>;

	#address-cells = <0>;
	interrupt-parent = <&sdhc_2>;
	interrupts = <0 1 2>;
	#interrupt-cells = <1>;
	interrupt-map-mask = <0xffffffff>;
	interrupt-map = <0 &intc 0 125 0
			1 &intc 0 221 0
			2 &msm_gpio 52 0>;
	interrupt-names = "hc_irq", "pwr_irq", "status_irq";
	cd-gpios = <&msm_gpio 52 0x1>;

	status = "ok";
};

/{
	mtp_batterydata: qcom,battery-data {
		qcom,batt-id-range-pct = <15>;
		#include "../qcom/batterydata-itech-3000mah-4200mv.dtsi"
		#include "../qcom/batterydata-itech-3000mah.dtsi"
	};
};

&pmi8950_fg {
	qcom,battery-data = <&mtp_batterydata>;
};

&pmi8950_charger {
	qcom,battery-data = <&mtp_batterydata>;
	qcom,chg-led-support;
	qcom,chg-led-sw-controls;
};

/* CoreSight */
&tpiu {
	pinctrl-names = "sdcard", "trace", "swduart",
			"swdtrc", "jtag", "spmi";
	/* NIDnT */
	pinctrl-0 = <&qdsd_clk_sdcard &qdsd_cmd_sdcard
		     &qdsd_data0_sdcard &qdsd_data1_sdcard
		     &qdsd_data2_sdcard &qdsd_data3_sdcard>;
	pinctrl-1 = <&qdsd_clk_trace &qdsd_cmd_trace
		     &qdsd_data0_trace &qdsd_data1_trace
		     &qdsd_data2_trace &qdsd_data3_trace>;
	pinctrl-2 = <&qdsd_cmd_swduart &qdsd_data0_swduart
		     &qdsd_data1_swduart &qdsd_data2_swduart
		     &qdsd_data3_swduart>;
	pinctrl-3 = <&qdsd_clk_swdtrc &qdsd_cmd_swdtrc
		     &qdsd_data0_swdtrc &qdsd_data1_swdtrc
		     &qdsd_data2_swdtrc &qdsd_data3_swdtrc>;
	pinctrl-4 = <&qdsd_cmd_jtag &qdsd_data0_jtag
		     &qdsd_data1_jtag &qdsd_data2_jtag
		     &qdsd_data3_jtag>;
	pinctrl-5 = <&qdsd_clk_spmi &qdsd_cmd_spmi
		     &qdsd_data0_spmi &qdsd_data3_spmi>;
};

&pm8950_1 {
	pm8950_cajon_dig: 8952_wcd_codec@f000 {
		compatible = "qcom,msm8x16_wcd_codec";
		status = "disabled";
		reg = <0xf000 0x100>;
		interrupt-parent = <&spmi_bus>;
		interrupts = <0x1 0xf0 0x0>,
			     <0x1 0xf0 0x1>,
			     <0x1 0xf0 0x2>,
			     <0x1 0xf0 0x3>,
			     <0x1 0xf0 0x4>,
			     <0x1 0xf0 0x5>,
			     <0x1 0xf0 0x6>,
			     <0x1 0xf0 0x7>;
		interrupt-names = "spk_cnp_int",
				  "spk_clip_int",
				  "spk_ocp_int",
				  "ins_rem_det1",
				  "but_rel_det",
				  "but_press_det",
				  "ins_rem_det",
				  "mbhc_int";

		cdc-vdda-cp-supply = <&pm8950_s4>;
		qcom,cdc-vdda-cp-voltage = <2050000 2050000>;
		qcom,cdc-vdda-cp-current = <500000>;

		cdc-vdda-rx-h-supply = <&pm8950_l5>;
		qcom,cdc-vdda-rx-h-voltage = <1800000 1800000>;
		qcom,cdc-vdda-rx-h-current = <5000>;

		cdc-vdda-tx-h-supply = <&pm8950_l5>;
		qcom,cdc-vdda-tx-h-voltage = <1800000 1800000>;
		qcom,cdc-vdda-tx-h-current = <5000>;

		cdc-vdd-px-supply = <&pm8950_l5>;
		qcom,cdc-vdd-px-voltage = <1800000 1800000>;
		qcom,cdc-vdd-px-current = <5000>;

		cdc-vdd-pa-supply = <&pm8950_s4>;
		qcom,cdc-vdd-pa-voltage = <2050000 2050000>;
		qcom,cdc-vdd-pa-current = <260000>;

		cdc-vdd-mic-bias-supply = <&pm8950_l13>;
		qcom,cdc-vdd-mic-bias-voltage = <3075000 3075000>;
		qcom,cdc-vdd-mic-bias-current = <5000>;

		qcom,cdc-mclk-clk-rate = <9600000>;

		qcom,cdc-static-supplies = "cdc-vdda-rx-h",
					   "cdc-vdda-tx-h",
					   "cdc-vdd-px",
					   "cdc-vdd-pa",
					   "cdc-vdda-cp";

		qcom,cdc-on-demand-supplies = "cdc-vdd-mic-bias";
		qcom,dig-cdc-base-addr = <0xc0f0000>;
	};

	pm8950_cajon_analog: 8952_wcd_codec@f100 {
		compatible = "qcom,msm8x16_wcd_codec";
		status = "disabled";
		reg = <0xf100 0x100>;
		interrupt-parent = <&spmi_bus>;
		interrupts = <0x1 0xf1 0x0>,
			     <0x1 0xf1 0x1>,
			     <0x1 0xf1 0x2>,
			     <0x1 0xf1 0x3>,
			     <0x1 0xf1 0x4>,
			     <0x1 0xf1 0x5>;
		interrupt-names = "ear_ocp_int",
				  "hphr_ocp_int",
				  "hphl_ocp_det",
				  "ear_cnp_int",
				  "hphr_cnp_int",
				  "hphl_cnp_int";
		qcom,dig-cdc-base-addr = <0xc0f0000>;
	};
};

&slim_msm {
	status = "disabled";
	/delete-node/ tasha_codec;
};
#include "../../../../../../drivers/video/msm/mdss/samsung/S6E3FA3_AMS598KH01/dsi_panel_S6E3FA3_AMS598KH01_fhd_octa_cmd.dtsi"
&pmx_mdss {
	qcom,num-grp-pins = <2>;
	qcom,pins = <&gp 25>, <&gp 38>;     // GPIO_25 : LCD_RST  // GPIO_38 : LCD_LDO_EN
};

&pmx_mdss_te {
	qcom,num-grp-pins = <1>;
	qcom,pins = <&gp 24>;       			// GPIO_24 : TE
};

&pmx_mdss_esd {
	qcom,num-grp-pins = <2>;
	qcom,pins = <&gp 133>, <&gp 115>; // GPIO_133 : FG-ERR  // GPIO_115 : DISP_DET
};

&ss_dsi_panel_S6E3FA3_AMS598KH01_FHD {
	samsung,panel-extra-power-gpio1 = <&msm_gpio 38 0>;
};

&mdss_dsi0 {
	qcom,dsi-pref-prim-pan = <&ss_dsi_panel_S6E3FA3_AMS598KH01_FHD>;

	qcom,platform-te-gpio = <&msm_gpio 24 0>;
	qcom,platform-reset-gpio = <&msm_gpio 25 0>;

	pinctrl-names = "mdss_default", "mdss_sleep";
	pinctrl-0 = <&mdss_dsi_active &mdss_te_active &mdss_esd_active>;
	pinctrl-1 = <&mdss_dsi_suspend &mdss_te_suspend &mdss_esd_suspend>;
};

&mdss_mdp {
	qcom,mdss-pref-prim-intf = "dsi";
};

&i2c_7 {
	mms_ts@48 {
		compatible = "melfas,mms_ts";
		reg = <0x48>;
		interrupt-parent = <&msm_gpio>;
		interrupts = <65 0x0>;
		/*vdd-io-supply = <&s2mpb02_l17>;*/
		/*vddo-supply = <&pm8950_l6>;*/

		pinctrl-names = "tsp_gpio_active", "tsp_gpio_suspend";
		pinctrl-0 = <&tsp_int_active>;
		pinctrl-1 = <&tsp_int_suspend>;

		melfas,vdd_en = <&pm8950_gpios 6 0x00>;
		melfas,irq-gpio = <&msm_gpio 65 0x0>;

		melfas,max_x = <2160>; /* <1080>; max x*/
		melfas,max_y = <3840>; /* <1920>; max y*/
		melfas,fw_name = "tsp_melfas/mms549_c9.fw";
		melfas,bringup = <0>;
		melfas,support_lpm;
		clocks = <&clock_gcc clk_gcc_blsp2_ahb_clk>,
			<&clock_gcc clk_gcc_blsp2_qup3_i2c_apps_clk>;
		clock-names = "iface_clk", "core_clk";

	};
};

&soc {
	/delete-node/ rome_vreg;
	/delete-node/ bt_vreg;
	/delete-node/ qcom,cnss_sdio;
};

/ {
	/delete-node/ bt_qca6174;
};

&pm8950_l3 {
	regulator-max-microvolt = <1050000>;
	regulator-min-microvolt = <1050000>;
};

&pm8950_l23 {
	regulator-max-microvolt = <1050000>;
	regulator-min-microvolt = <1050000>;
};
